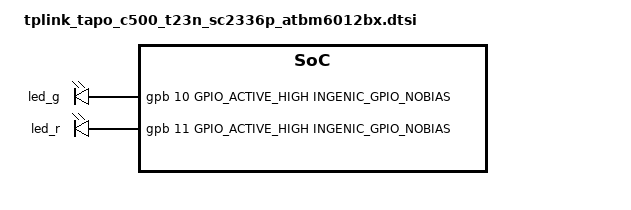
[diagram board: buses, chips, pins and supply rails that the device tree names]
// TP-Link Tapo C500 EU/2.0 (T23N, SC2336P, ATBM6012BX) per-board GPIO definitions.
// Injected into the kernel 4.4+ device tree; ignored on 3.10.

#include <dt-bindings/gpio/gpio.h>
#include <dt-bindings/pinctrl/ingenic-pinctrl.h>

/ {
	gpio-leds {
		compatible = "gpio-leds";

		led_g {
			label = "led_g";
			gpios = <&gpb 10 GPIO_ACTIVE_HIGH INGENIC_GPIO_NOBIAS>;
			default-state = "off";
		};

		led_r {
			label = "led_r";
			gpios = <&gpb 11 GPIO_ACTIVE_HIGH INGENIC_GPIO_NOBIAS>;
			default-state = "off";
		};
	};
};

/* Card detect; the family tree carries the reference pin. */
&msc0 {
	ingenic,cd-gpios = <&gpb 9 GPIO_ACTIVE_LOW INGENIC_GPIO_PULLUP>;
};
